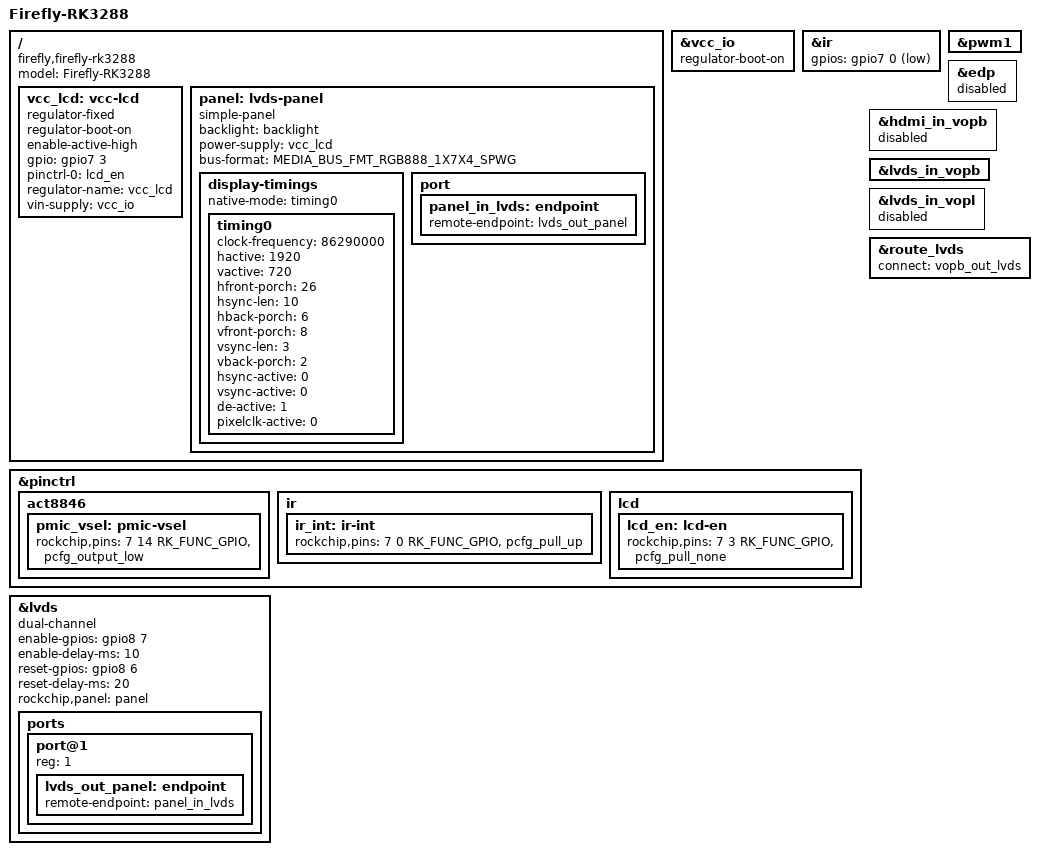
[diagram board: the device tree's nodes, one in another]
/*
 * Copyright (c) 2014, 2015 FUKAUMI Naoki <naobsd@gmail.com>
 *
 * This file is dual-licensed: you can use it either under the terms
 * of the GPL or the X11 license, at your option. Note that this dual
 * licensing only applies to this file, and not this project as a
 * whole.
 *
 *  a) This file is free software; you can redistribute it and/or
 *     modify it under the terms of the GNU General Public License as
 *     published by the Free Software Foundation; either version 2 of the
 *     License, or (at your option) any later version.
 *
 *     This file is distributed in the hope that it will be useful,
 *     but WITHOUT ANY WARRANTY; without even the implied warranty of
 *     MERCHANTABILITY or FITNESS FOR A PARTICULAR PURPOSE.  See the
 *     GNU General Public License for more details.
 *
 * Or, alternatively,
 *
 *  b) Permission is hereby granted, free of charge, to any person
 *     obtaining a copy of this software and associated documentation
 *     files (the "Software"), to deal in the Software without
 *     restriction, including without limitation the rights to use,
 *     copy, modify, merge, publish, distribute, sublicense, and/or
 *     sell copies of the Software, and to permit persons to whom the
 *     Software is furnished to do so, subject to the following
 *     conditions:
 *
 *     The above copyright notice and this permission notice shall be
 *     included in all copies or substantial portions of the Software.
 *
 *     THE SOFTWARE IS PROVIDED "AS IS", WITHOUT WARRANTY OF ANY KIND,
 *     EXPRESS OR IMPLIED, INCLUDING BUT NOT LIMITED TO THE WARRANTIES
 *     OF MERCHANTABILITY, FITNESS FOR A PARTICULAR PURPOSE AND
 *     NONINFRINGEMENT. IN NO EVENT SHALL THE AUTHORS OR COPYRIGHT
 *     HOLDERS BE LIABLE FOR ANY CLAIM, DAMAGES OR OTHER LIABILITY,
 *     WHETHER IN AN ACTION OF CONTRACT, TORT OR OTHERWISE, ARISING
 *     FROM, OUT OF OR IN CONNECTION WITH THE SOFTWARE OR THE USE OR
 *     OTHER DEALINGS IN THE SOFTWARE.
 */

/dts-v1/;
#include "rk3288-firefly.dtsi"
#include "rk3288-linux.dtsi"

/ {
	model = "Firefly-RK3288";
	compatible = "firefly,firefly-rk3288", "rockchip,rk3288";

	// vcc_lcd: vcc-lcd {
	// 	compatible = "regulator-fixed";
	// 	regulator-boot-on;
	// 	enable-active-high;
	// 	gpio = <&gpio7 3 GPIO_ACTIVE_HIGH>;
	// 	pinctrl-names = "default";
	// 	pinctrl-0 = <&lcd_en>;
	// 	regulator-name = "vcc_lcd";
	// 	vin-supply = <&vcc_io>;
	// };

	vcc_lcd: vcc-lcd {
		compatible = "regulator-fixed";
		regulator-boot-on;
		enable-active-high;
		gpio = <&gpio7 3 GPIO_ACTIVE_HIGH>;
		pinctrl-names = "default";
		pinctrl-0 = <&lcd_en>;
		regulator-name = "vcc_lcd";
		vin-supply = <&vcc_io>;
	};

    panel: lvds-panel {
        compatible = "simple-panel";
        backlight = <&backlight>;

		// avdd1v0-supply = <&vdd10_lcd>;
		// avdd1v8-supply = <&vcc18_lcd>;
		// avdd3v3-supply = <&vcca_33>;
        power-supply = <&vcc_lcd>;


        bus-format = <MEDIA_BUS_FMT_RGB888_1X7X4_SPWG>;

        display-timings {
            native-mode = <&timing0>;

            timing0: timing0 {
                clock-frequency = <86290000>;
                hactive = <1920>;
                vactive = <720>;
                hfront-porch = <26>;
                hsync-len = <10>;
                hback-porch = <6>;
                vfront-porch = <8>;
                vsync-len = <3>;
                vback-porch = <2>;
                hsync-active = <0>;
                vsync-active = <0>;
                de-active = <1>;
                pixelclk-active = <0>;
            };
        };

        port {
            panel_in_lvds: endpoint{
                remote-endpoint = <&lvds_out_panel>;
            };
        };
    };
};

&vcc_io {
	regulator-boot-on;
};

&ir {
	gpios = <&gpio7 0 GPIO_ACTIVE_LOW>;
};

&pinctrl {
	act8846 {
		pmic_vsel: pmic-vsel {
			rockchip,pins = <7 14 RK_FUNC_GPIO &pcfg_output_low>;
		};
	};

	ir {
		ir_int: ir-int {
			rockchip,pins = <7 0 RK_FUNC_GPIO &pcfg_pull_up>;
		};
	};

	lcd {
		lcd_en: lcd-en  {
			rockchip,pins = <7 3 RK_FUNC_GPIO &pcfg_pull_none>;
		};
	};
};

&pwm1 {
	status = "okay";
};

&edp {
	status = "disable";
};

&hdmi_in_vopb {
	status = "disable";
};

&lvds_in_vopb {
	status = "okay";
};

&lvds_in_vopl {
	status = "disable";
};

&route_lvds {
    connect = <&vopb_out_lvds>;
	status = "okay";
};

&lvds {
    dual-channel;
	status = "okay";
	enable-gpios = <&gpio8 7 GPIO_ACTIVE_HIGH>;
	enable-delay-ms = <10>;
	reset-gpios = <&gpio8 6 GPIO_ACTIVE_HIGH>;
	reset-delay-ms = <20>;
    rockchip,panel = <&panel>;

    ports {
        port@1 {
            reg = <1>;

            lvds_out_panel: endpoint {
                remote-endpoint = <&panel_in_lvds>;
            };
        };
    };
};

// lvds_panel {
// 	status = "okay";
// 	compatible ="simple-panel";
// 	backlight = <&backlight>;
// 	enable-gpios = <&gpio7 4 GPIO_ACTIVE_HIGH>;
// 	enable-delay-ms = <10>;
// 	power-supply = <&vcc_lcd>;
// 	bus-format = <MEDIA_BUS_FMT_RGB888_1X7X4_SPWG>;

// 	display-timings {
// 		native-mode = <&timing0>;
// 		timing0: timing0 {
// 			clock-frequency = <86290000>;
// 			hactive = <1920>;
// 			vactive = <720>;
// 			hfront-porch = <26>;
// 			hsync-len = <10>;
// 			hback-porch = <6>;
// 			vfront-porch = <8>;
// 			vsync-len = <3>;
// 			vback-porch = <2>;
// 			hsync-active = <0>;
// 			vsync-active = <0>;
// 			de-active = <1>;
// 			pixelclk-active = <0>;
// 		};
// 	};
// };

